AUTOSAR XML (schema 00048)
package /ComponentTypes
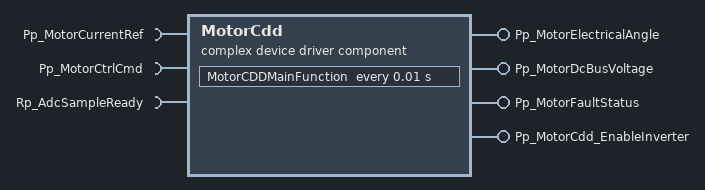
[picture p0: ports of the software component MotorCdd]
  complex device driver sw component type MotorCdd
    4 x provide port:
      Pp_MotorElectricalAngle: nonqueued-sender-com-spec{data-element=ElectricAngle, init-value=0}, provided-interface=Pp_MotorElectricalAngle
      Pp_MotorDcBusVoltage: nonqueued-sender-com-spec{data-element=Vbus, init-value=0}, provided-interface=Pp_MotorDcBusVoltage
      Pp_MotorFaultStatus: nonqueued-sender-com-spec{data-element=tle9180_Ov_Fault, init-value=0}, provided-interface=Pp_MotorFaultStatus
      Pp_MotorCdd_EnableInverter: server-com-spec{operation=EnableInverter, queue-length=1}, provided-interface=Pp_MotorCdd_EnableInverter
    require port Pp_MotorCurrentRef: required-interface=Pp_MotorCurrentRef
      required-com-specs:
        data-element=Iq_Ref, filter=data-filter-type=ALWAYS, init-value=0
        data-element=Id_Ref, filter=data-filter-type=ALWAYS, init-value=0
    require port Pp_MotorCtrlCmd: nonqueued-receiver-com-spec{data-element=MotorMode, filter=data-filter-type=ALWAYS, init-value=0}, required-interface=Pp_MotorCtrlCmd
    require port Rp_AdcSampleReady: required-interface=Rp_AdcSampleReady
    behavior MotorCdd_InternalBehavior: data-type-mapping=MotorDataTypeMappingSet
      timing event TMT_MotorCDDMainFunction: start-on-event=MotorCDDMainFunction, period=0.01
      init event MotorCdd_InitEvent: start-on-event=MotorCdd_Init
      operation invoked event OIT_MotorPp_MotorCdd_EnableInverter_EnableInverterswitch_Pp_MotorCdd_EnableInverter_EnableInverter: start-on-event=Pp_MotorCdd_EnableInverter_EnableInverter, operation=Pp_MotorCdd_EnableInverter.EnableInverter
      external trigger occurred event EXTO_MotorCdd_AdcOnSampleReady_If_AdcSampleReady_Rp_AdcSampleReady: start-on-event=MotorCdd_AdcOnSampleReady, trigger=Rp_AdcSampleReady.AdcSampleReady
      4 x runnable:
        MotorCDDMainFunction
          data-receive-point-by-arguments:
            access REC_Pp_MotorCtrlCmd_MotorMode: accessed-variable=Pp_MotorCtrlCmd.MotorMode
            access REC_Pp_MotorCurrentRef_Id_Ref: accessed-variable=Pp_MotorCurrentRef.Id_Ref
            access REC_Pp_MotorCurrentRef_Iq_Ref: accessed-variable=Pp_MotorCurrentRef.Iq_Ref
          data-send-points:
            access SEND_Pp_MotorFaultStatus_tle9180_Ov_Fault: accessed-variable=Pp_MotorFaultStatus.tle9180_Ov_Fault
            access SEND_Pp_MotorDcBusVoltage_Vbus: accessed-variable=Pp_MotorDcBusVoltage.Vbus
            access SEND_Pp_MotorElectricalAngle_ElectricAngle: accessed-variable=Pp_MotorElectricalAngle.ElectricAngle
        MotorCdd_Init
        Pp_MotorCdd_EnableInverter_EnableInverter
        MotorCdd_AdcOnSampleReady
  swc implementation MotorCdd_Implementation: behavior=MotorCdd_InternalBehavior
